VERSION ""

NS_ :

BS_:

BU_: ECU BPS BottomDist Motor

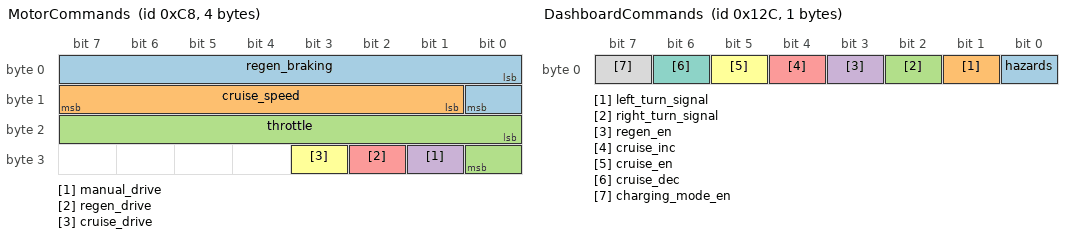
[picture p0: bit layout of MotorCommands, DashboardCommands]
BO_ 200 MotorCommands: 4 Motor
 SG_ regen_braking : 0|9@1+ (1,0) [0|256] "" Vector__XXX
 SG_ cruise_speed : 9|7@1+ (1,0) [0|127] "" Vector__XXX
 SG_ throttle : 16|9@1+ (1,0) [0|256] "" Vector__XXX
 SG_ manual_drive : 25|1@1+ (1,0) [0|1] "" Vector__XXX
 SG_ regen_drive : 26|1@1+ (1,0) [0|1] "" Vector__XXX
 SG_ cruise_drive : 27|1@1+ (1,0) [0|1] "" Vector__XXX

BO_ 300 DashboardCommands: 1 ECU
 SG_ hazards : 0|1@1+ (1,0) [0|1] "" Vector__XXX
 SG_ left_turn_signal : 1|1@1+ (1,0) [0|1] "" Vector__XXX
 SG_ right_turn_signal : 2|1@1+ (1,0) [0|1] "" Vector__XXX
 SG_ regen_en : 3|1@1+ (1,0) [0|1] "" Vector__XXX
 SG_ cruise_inc : 4|1@1+ (1,0) [0|1] "" Vector__XXX
 SG_ cruise_en : 5|1@1+ (1,0) [0|1] "" Vector__XXX
 SG_ cruise_dec : 6|1@1+ (1,0) [0|1] "" Vector__XXX
 SG_ charging_mode_en : 7|1@1+ (1,0) [0|1] "" Vector__XXX

BO_ 500 PedalStatus: 3 BottomDist
 SG_ throttle_pedal : 0|12@1+ (1,0) [0|4095] "" Vector__XXX
 SG_ brake_pedal : 12|12@1+ (1,0) [0|4095] "" Vector__XXX

BO_ 938 BpsError: 4 BPS
 SG_ internal_cell_communication_fault : 0|1@1+ (1,0) [0|1] "" Vector__XXX

BA_DEF_  "BusType" STRING ;
BA_DEF_DEF_  "BusType" "CAN";
